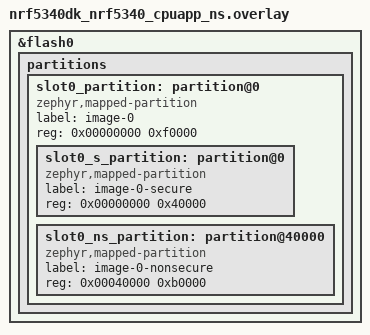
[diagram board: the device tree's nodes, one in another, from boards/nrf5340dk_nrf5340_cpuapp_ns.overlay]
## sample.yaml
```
sample:
  description: Sample showing Profiler usage
  name: Profiler sample
tests:
  sample.nrf_profiler:
    sysbuild: true
    build_only: true
    integration_platforms:
      - nrf52dk/nrf52832
      - nrf5340dk/nrf5340/cpuapp/ns
      - nrf9160dk/nrf9160/ns
    platform_allow:
      - nrf52dk/nrf52832
      - nrf52840dk/nrf52840
      - nrf5340dk/nrf5340/cpuapp/ns
      - nrf9160dk/nrf9160/ns
      - nrf21540dk/nrf52840
    platform_exclude:
      - native_sim
      - qemu_x86
      - qemu_cortex_m3
    tags:
      - ci_build
      - sysbuild
      - ci_samples_nrf_profiler
```

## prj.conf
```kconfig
#
# Copyright (c) 2019 Nordic Semiconductor ASA
#
# SPDX-License-Identifier: LicenseRef-Nordic-5-Clause
#
# Configuration required by Profiler
CONFIG_USE_SEGGER_RTT=y
CONFIG_NRF_PROFILER=y
CONFIG_NRF_PROFILER_NORDIC=y

# Using console with UART
CONFIG_CONSOLE=y
CONFIG_UART_CONSOLE=y
CONFIG_RTT_CONSOLE=n
```

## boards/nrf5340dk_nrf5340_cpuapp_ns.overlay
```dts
/*
 * Copyright (c) 2026 Nordic Semiconductor ASA
 *
 * SPDX-License-Identifier: LicenseRef-Nordic-5-Clause
 */

/*
 * No bootloader is built in this configuration.
 * The default nRF5340 partition layout reserves the first 64 KB for MCUboot.
 * The TF-M storage and settings partitions from the board devicetree
 * (0xf0000 onwards) are kept and still used.
 */
/delete-node/ &boot_partition;
/delete-node/ &slot0_partition;
/delete-node/ &slot1_partition;

&flash0 {
	partitions {
		slot0_partition: partition@0 {
			compatible = "zephyr,mapped-partition";
			label = "image-0";
			reg = <0x00000000 0xf0000>;
			ranges = <0x0 0x0 0xf0000>;
			#address-cells = <1>;
			#size-cells = <1>;

			slot0_s_partition: partition@0 {
				compatible = "zephyr,mapped-partition";
				label = "image-0-secure";
				reg = <0x00000000 0x40000>;
			};

			slot0_ns_partition: partition@40000 {
				compatible = "zephyr,mapped-partition";
				label = "image-0-nonsecure";
				reg = <0x00040000 0xb0000>;
			};
		};
	};
};

/*
 * This layout redefines the flash partition map, dropping partitions that the
 * upstream nordic-tz-secure/-nonsecure descriptors reference. Remove the
 * descriptors so they do not hold dangling phandles (restores the behaviour
 * from before the descriptors were introduced).
 */
/ {
	/delete-node/ nordic-tz-secure;
	/delete-node/ nordic-tz-nonsecure;
};
```

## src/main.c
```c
/*
 * Copyright (c) 2019 Nordic Semiconductor ASA
 *
 * SPDX-License-Identifier: LicenseRef-Nordic-5-Clause
 */

#include <zephyr/kernel.h>
#include <nrf_profiler.h>
#include <stdio.h>

#define MAX_VAL1 1000
#define MAX_VAL4 100
#define MAX_BUF_SIZE 256

static uint16_t data_event_id;
static uint16_t no_data_event_id;

static void profile_no_data_event(void)
{
	struct log_event_buf buf;

	nrf_profiler_log_start(&buf);
	nrf_profiler_log_send(&buf, no_data_event_id);
}

static void profile_data_event(uint32_t val1, int32_t val2, int16_t val3,
			       uint8_t val4, const char *string)
{
	struct log_event_buf buf;

	nrf_profiler_log_start(&buf);
	/* Use this function for 32-bit data type */
	nrf_profiler_log_encode_uint32(&buf, val1);
	nrf_profiler_log_encode_int32(&buf, val2);
	/* Use this function for 16-bit data type */
	nrf_profiler_log_encode_int16(&buf, val3);
	/* Use this function for 8-bit data type */
	nrf_profiler_log_encode_uint8(&buf, val4);
	/* Use this function for string data type */
	nrf_profiler_log_encode_string(&buf, string);

	nrf_profiler_log_send(&buf, data_event_id);
}

static void register_nrf_profiler_events(void)
{
	static const char * const data_names[] = {"value1", "value2", "value3", "value4", "string"};
	static const enum nrf_profiler_arg data_types[] = {NRF_PROFILER_ARG_U32,
						    NRF_PROFILER_ARG_S32, NRF_PROFILER_ARG_S16,
						    NRF_PROFILER_ARG_U8, NRF_PROFILER_ARG_STRING};

	no_data_event_id = nrf_profiler_register_event_type("no data event", NULL,
							NULL, 0);
	data_event_id = nrf_profiler_register_event_type("data event", data_names,
						     data_types, 5);
}

int main(void)
{
	if (nrf_profiler_init()) {
		printk("Profiler failed to initialize\n");
	};
	printk("Profiler initialized\n");
	register_nrf_profiler_events();
	printk("Events registered\n");
	uint32_t val1 = 50;
	int32_t val2 = -50;
	int16_t val3 = -10;
	uint8_t val4 = 7;

	/* Periodically changing values and profiling events */
	while (1) {
		val2 = -val2;
		val3 = -val3;
		val1++;
		val4++;

		if (val1 > MAX_VAL1) {
			val1 = 0;
		}

		if (val4 > MAX_VAL4) {
			val4 = 0;
		}

		char string[MAX_BUF_SIZE];
		int err = snprintf(string, sizeof(string),
				   "Sum of values is: %d.", val1 + val2 + val3 + val4);

		if ((err < 0) || (err >= sizeof(string))) {
			printk("snprintf error: %d\n", err);
			return 0;
		}

		profile_no_data_event();
		k_sleep(K_MSEC(10));
		profile_data_event(val1, val2, val3, val4, string);
		printk("Events sent\n");
		k_sleep(K_MSEC(500));
	}

}
```
